# OCP_SOCKET_PRM register map
Vendor: Texas Instruments
Peripheral module from a debugger description file (folder omap5430_ES2_PUBLIC).
Registers are 32-bit, access per field, reset 0x0 unless marked. A register's access mark holds for its fields unless they carry their own. Offsets are as the file gives them; lines under a group give offsets from that group; [hi:lo] are bit positions; {n}, {i} and the like mark numbered series; 'fields as' and 'values as' point back to an identical list; <NAME> marks a mode.

## OCP_SOCKET_PRM
0x00 REVISION_PRM ro reset not defined — This register contains the IP revision code for the PRM part of the PRCM
  [31:0] REV — Revision Number
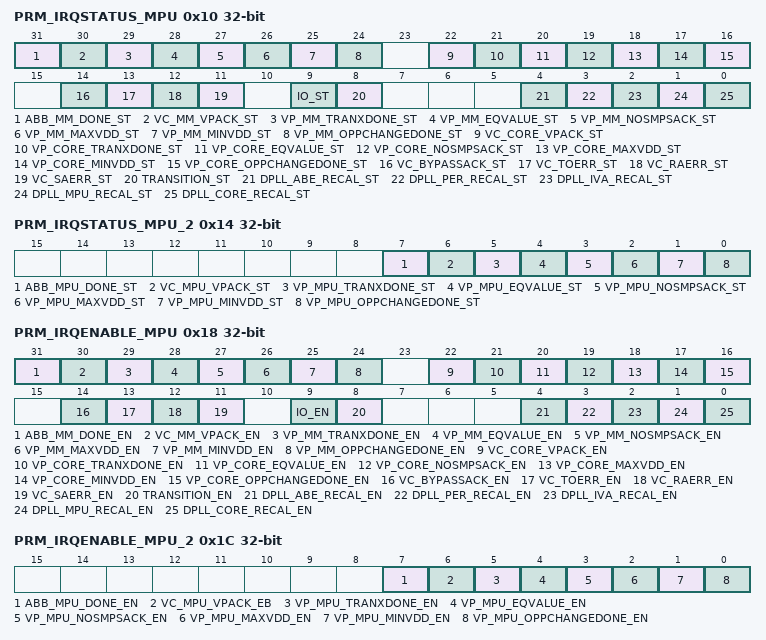
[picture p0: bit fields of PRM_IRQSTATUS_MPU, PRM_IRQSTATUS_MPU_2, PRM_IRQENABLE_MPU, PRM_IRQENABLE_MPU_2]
0x10 PRM_IRQSTATUS_MPU access not given — This register provides status on MPU interrupt events. Any event is logged independently of the corresponding IRQENABLE value. SW is required to clear a set bit by writing a '1' into the bit-position to be cleared.
  [all] fields
    0=IRQ_fal (No interrupt); 1=IRQ_tru (Interrupt is pending)
  [31] ABB_MM_DONE_ST — MM ABB mode change done. This status is set when OPP_CHANGE bit is cleared by hardware in PRM_ABBLDO_MM_CRTL register. It is cleared by SW. (access RW W1toClr)
  [30] VC_MM_VPACK_ST — Voltage Controller MM voltage processor command acknowledge status. (access RW W1toClr)
  [29] VP_MM_TRANXDONE_ST — Voltage Processor MM transaction completion status. This status is set when a transaction is completed in the voltage processor. It is cleared by SW. (access RW W1toClr)
  [28] VP_MM_EQVALUE_ST — Voltage Processor MM voltage value change event. This status is set when an update has been requested but the new voltage value is the same as the current SMPS voltage value. It is cleared by SW. (access RW W1toClr)
  [27] VP_MM_NOSMPSACK_ST — Voltage Processor MM timeout event status. This status is set when the timeout occured before the SMPS acknowledge. It is cleared by SW. (access RW W1toClr)
  [26] VP_MM_MAXVDD_ST — Voltage Processor MM voltage higher limit event status. This status is set when the voltage higher limit is reached. It is cleared by SW. (access RW W1toClr)
  [25] VP_MM_MINVDD_ST — Voltage Processor MM voltage lower limit event status. This status is set when the voltage lower limit is reached. It is cleared by SW. (access RW W1toClr)
  [24] VP_MM_OPPCHANGEDONE_ST — Voltage Processor MM OPP change done status, including ABB mode change done if applicable (OPP_CHANGE bit cleared in PRM_ABBLDO_MM_CRTL). It is cleared by SW. (access RW W1toClr)
  [22] VC_CORE_VPACK_ST — Voltage Controller CORE voltage processor command acknowledge status (access RW W1toClr)
  [21] VP_CORE_TRANXDONE_ST — Voltage Processor CORE transaction completion status. This status is set when a transaction is completed in the voltage processor. It is cleared by SW. (access RW W1toClr)
  [20] VP_CORE_EQVALUE_ST — Voltage Processor CORE voltage value change event. This status is set when an update has been requested but the new voltage value is the same as the current SMPS voltage value. It is cleared by SW. (access RW W1toClr)
  [19] VP_CORE_NOSMPSACK_ST — Voltage Processor CORE timeout event status. This status is set when the timeout occured before the SMPS acknowledge. It is cleared by SW. (access RW W1toClr)
  [18] VP_CORE_MAXVDD_ST — Voltage Processor CORE voltage higher limit event status. This status is set when the voltage higher limit is reached. It is cleared by SW. (access RW W1toClr)
  [17] VP_CORE_MINVDD_ST — Voltage Processor CORE voltage lower limit event status. This status is set when the voltage lower limit is reached. It is cleared by SW. (access RW W1toClr)
  [16] VP_CORE_OPPCHANGEDONE_ST — Voltage Processor CORE OPP change done status. It is cleared by SW. (access RW W1toClr)
  [14] VC_BYPASSACK_ST — Voltage Controller bypass command acknowledge status. (access RW W1toClr)
  [13] VC_TOERR_ST — Voltage Controller timeout error event status. (access RW W1toClr)
  [12] VC_RAERR_ST — Voltage Controller register address acknowledge error event status. (access RW W1toClr)
  [11] VC_SAERR_ST — Voltage Controller slave address acknowledge error event status. (access RW W1toClr)
  [9] IO_ST — IO pad event interrupt status. (access RW W1toClr)
  [8] TRANSITION_ST — Software supervised transition completed event interrupt status (any domain). Asserted upon completion of any clock domain force wakeup transition or upon completion of any power domain sleep transition with at least one enclosed clock domain configured in forced-sleep. (access RW W1toClr)
  [4] DPLL_ABE_RECAL_ST — ABE DPLL recalibration interrupt status. (access RW W1toClr)
  [3] DPLL_PER_RECAL_ST — PER DPLL recalibration interrupt status. (access RW W1toClr)
  [2] DPLL_IVA_RECAL_ST — IVA DPLL recalibration interrupt status. (access RW W1toClr)
  [1] DPLL_MPU_RECAL_ST — MPU DPLL recalibration interrupt status. (access RW W1toClr)
  [0] DPLL_CORE_RECAL_ST — CORE DPLL recalibration interrupt status. (access RW W1toClr)
0x14 PRM_IRQSTATUS_MPU_2 access not given — This register provides status on MPU interrupt events. Any event is logged independently of the corresponding IRQENABLE value. SW is required to clear a set bit by writing a '1' into the bit-position to be cleared.
  [all] fields
    0=IRQ_fal (No interrupt); 1=IRQ_tru (Interrupt is pending)
  [7] ABB_MPU_DONE_ST — MPU ABB mode change done. This status is set when OPP_CHANGE bit is cleared by hardware in PRM_ABBLDO_MPU_CRTL register. It is cleared by SW. (access RW W1toClr)
  [6] VC_MPU_VPACK_ST — Voltage Controller MPU voltage processor command acknowledge status. (access RW W1toClr)
  [5] VP_MPU_TRANXDONE_ST — Voltage Processor MPU transaction completion status. This status is set when a transaction is completed in the voltage processor. It is cleared by SW. (access RW W1toClr)
  [4] VP_MPU_EQVALUE_ST — Voltage Processor MPU voltage value change event. This status is set when an update has been requested but the new voltage value is the same as the current SMPS voltage value. It is cleared by SW. (access RW W1toClr)
  [3] VP_MPU_NOSMPSACK_ST — Voltage Processor MPU timeout event status. This status is set when the timeout occured before the SMPS acknowledge. It is cleared by SW. (access RW W1toClr)
  [2] VP_MPU_MAXVDD_ST — Voltage Processor MPU voltage higher limit event status. This status is set when the voltage higher limit is reached. It is cleared by SW. (access RW W1toClr)
  [1] VP_MPU_MINVDD_ST — Voltage Processor MPU voltage lower limit event status. This status is set when the voltage lower limit is reached. It is cleared by SW. (access RW W1toClr)
  [0] VP_MPU_OPPCHANGEDONE_ST — Voltage Processor MPU OPP change done status, including ABB mode change done if applicable (OPP_CHANGE bit cleared in PRM_ABBLDO_MPU_CRTL). It is cleared by SW. (access RW W1toClr)
0x18 PRM_IRQENABLE_MPU — This register is used to enable or disable MPU interrupt activation upon presence of corresponding bit.
  [31] ABB_MM_DONE_EN rw — MM ABB mode change done enable.
    0=IRQ_fal (Interrupt is masked); 1=IRQ_tru (Interrupt is enabled)
  [30] VC_MM_VPACK_EN rw — Voltage Controller MM voltage processor command acknowledge enable.
    0=irq_msk (Interrupt is masked); 1=irq_en (Interrupt is enabled)
  [29] VP_MM_TRANXDONE_EN rw — Voltage Processor MM transaction completion enable.
    values as VC_MM_VPACK_EN
  [28] VP_MM_EQVALUE_EN rw — Voltage Processor MM voltage value change event enable.
    values as VC_MM_VPACK_EN
  [27] VP_MM_NOSMPSACK_EN rw — Voltage Processor MM timeout event enable.
    values as VC_MM_VPACK_EN
  [26] VP_MM_MAXVDD_EN rw — Voltage Processor MM voltage higher limit event enable.
    values as VC_MM_VPACK_EN
  [25] VP_MM_MINVDD_EN rw — Voltage Processor MM voltage lower limit event enable.
    values as VC_MM_VPACK_EN
  [24] VP_MM_OPPCHANGEDONE_EN rw — Voltage Processor MM OPP change done enable.
    values as VC_MM_VPACK_EN
  [22] VC_CORE_VPACK_EN rw — Voltage Controller CORE voltage processor command acknowledge enable
    values as VC_MM_VPACK_EN
  [21] VP_CORE_TRANXDONE_EN rw — Voltage Processor CORE transaction completion enable.
    values as VC_MM_VPACK_EN
  [20] VP_CORE_EQVALUE_EN rw — Voltage Processor CORE voltage value change event enable.
    values as VC_MM_VPACK_EN
  [19] VP_CORE_NOSMPSACK_EN rw — Voltage Processor CORE timeout event enable.
    values as VC_MM_VPACK_EN
  [18] VP_CORE_MAXVDD_EN rw — Voltage Processor CORE voltage higher limit event enable.
    values as VC_MM_VPACK_EN
  [17] VP_CORE_MINVDD_EN rw — Voltage Processor CORE voltage lower limit event enable.
    values as VC_MM_VPACK_EN
  [16] VP_CORE_OPPCHANGEDONE_EN rw — Voltage Processor CORE OPP change done enable.
    values as VC_MM_VPACK_EN
  [14] VC_BYPASSACK_EN rw — Voltage Controller bypass command acknowledge enable.
    values as VC_MM_VPACK_EN
  [13] VC_TOERR_EN rw — Voltage Controller timeout error event enable.
    values as VC_MM_VPACK_EN
  [12] VC_RAERR_EN rw — Voltage Controller register address acknowledge error event enable.
    values as VC_MM_VPACK_EN
  [11] VC_SAERR_EN rw — Voltage Controller slave address acknowledge error event enable.
    values as VC_MM_VPACK_EN
  [9] IO_EN rw — IO pad event interrupt enable.
    values as VC_MM_VPACK_EN
  [8] TRANSITION_EN rw — Software supervised transition completed event interrupt enable (any domain).
    values as VC_MM_VPACK_EN
  [4] DPLL_ABE_RECAL_EN rw — ABE DPLL recalibration interrupt enable.
    values as VC_MM_VPACK_EN
  [3] DPLL_PER_RECAL_EN rw — PER DPLL recalibration interrupt enable.
    values as VC_MM_VPACK_EN
  [2] DPLL_IVA_RECAL_EN rw — IVA DPLL recalibration interrupt enable.
    values as VC_MM_VPACK_EN
  [1] DPLL_MPU_RECAL_EN rw — MPU DPLL recalibration interrupt enable.
    values as VC_MM_VPACK_EN
  [0] DPLL_CORE_RECAL_EN rw — CORE DPLL recalibration interrupt enable.
    values as VC_MM_VPACK_EN
0x1C PRM_IRQENABLE_MPU_2 — This register is used to enable or disable MPU interrupt activation upon presence of corresponding bit.
  [7] ABB_MPU_DONE_EN rw — MPU ABB mode change done enable.
    values as PRM_IRQENABLE_MPU.ABB_MM_DONE_EN
  [6] VC_MPU_VPACK_EB rw — Voltage Controller MPU voltage processor command acknowledge enable.
    0=Interrupt_is_masked; 1=Interrupt_is_enabled
  [5] VP_MPU_TRANXDONE_EN rw — Voltage Processor MPU transaction completion enable
    values as PRM_IRQENABLE_MPU.VC_MM_VPACK_EN
  [4] VP_MPU_EQVALUE_EN rw — Voltage Processor MPU voltage value change event enable
    values as PRM_IRQENABLE_MPU.VC_MM_VPACK_EN
  [3] VP_MPU_NOSMPSACK_EN rw — Voltage Processor MPU timeout event enable
    values as PRM_IRQENABLE_MPU.VC_MM_VPACK_EN
  [2] VP_MPU_MAXVDD_EN rw — Voltage Processor MPU voltage higher limit event enable
    values as PRM_IRQENABLE_MPU.VC_MM_VPACK_EN
  [1] VP_MPU_MINVDD_EN rw — Voltage Processor MPU voltage lower limit event enable
    values as PRM_IRQENABLE_MPU.VC_MM_VPACK_EN
  [0] VP_MPU_OPPCHANGEDONE_EN rw — Voltage Processor MPU OPP change done enable
    values as PRM_IRQENABLE_MPU.VC_MM_VPACK_EN
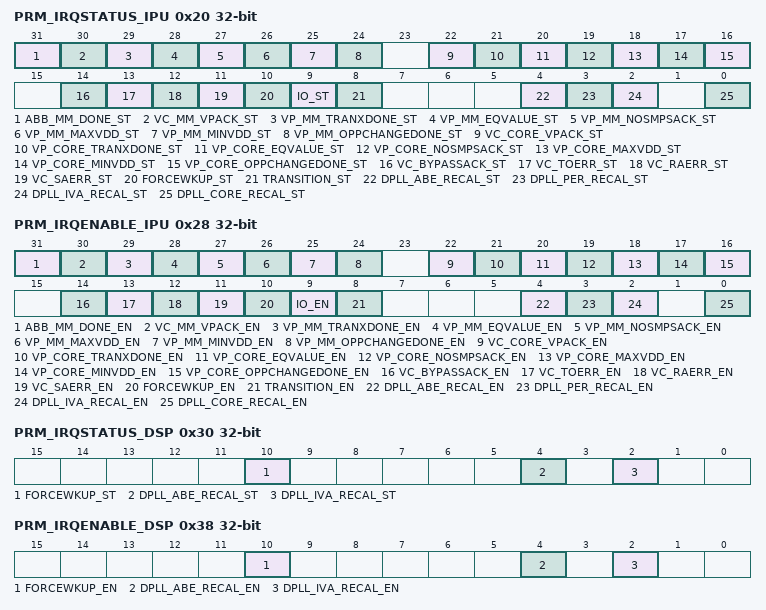
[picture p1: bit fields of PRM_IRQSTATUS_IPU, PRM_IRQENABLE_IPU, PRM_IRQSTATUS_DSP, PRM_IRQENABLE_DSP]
0x20 PRM_IRQSTATUS_IPU access not given — This register provides status on IPU interrupt events. Any event is logged independently of the corresponding IRQENABLE value. SW is required to clear a set bit by writing a '1' into the bit-position to be cleared.
  [all] fields
    0=IRQ_fal (No interrupt); 1=IRQ_tru (Interrupt is pending)
  [31] ABB_MM_DONE_ST — MM ABB mode change done. This status is set when OPP_CHANGE bit is cleared by hardware in PRM_ABBLDO_MM_CRTL register. It is cleared by SW. (access RW W1toClr)
  [30] VC_MM_VPACK_ST — Voltage Controller MM voltage processor command acknowledge status (access RW W1toClr)
  [29] VP_MM_TRANXDONE_ST — Voltage Processor MM transaction completion status. This status is set when a transaction is completed in the voltage processor. It is cleared by SW. (access RW W1toClr)
  [28] VP_MM_EQVALUE_ST — Voltage Processor MM voltage value change event. This status is set when an update has been requested but the new voltage value is the same as the current SMPS voltage value. It is cleared by SW. (access RW W1toClr)
  [27] VP_MM_NOSMPSACK_ST — Voltage Processor MM timeout event status. This status is set when the timeout occured before the SMPS acknowledge. It is cleared by SW. (access RW W1toClr)
  [26] VP_MM_MAXVDD_ST — Voltage Processor MM voltage higher limit event status. This status is set when the voltage higher limit is reached. It is cleared by SW. (access RW W1toClr)
  [25] VP_MM_MINVDD_ST — Voltage Processor MM voltage lower limit event status. This status is set when the voltage lower limit is reached. It is cleared by SW. (access RW W1toClr)
  [24] VP_MM_OPPCHANGEDONE_ST — Voltage Processor MM OPP change done status, including ABB mode change done if applicable (OPP_CHANGE bit cleared in PRM_ABBLDO_MM_CRTL). It is cleared by SW. (access RW W1toClr)
  [22] VC_CORE_VPACK_ST — Voltage Controller CORE voltage processor command acknowledge status (access RW W1toClr)
  [21] VP_CORE_TRANXDONE_ST — Voltage Processor CORE transaction completion status. This status is set when a transaction is completed in the voltage processor. It is cleared by SW. (access RW W1toClr)
  [20] VP_CORE_EQVALUE_ST — Voltage Processor CORE voltage value change event. This status is set when an update has been requested but the new voltage value is the same as the current SMPS voltage value. It is cleared by SW. (access RW W1toClr)
  [19] VP_CORE_NOSMPSACK_ST — Voltage Processor CORE timeout event status. This status is set when the timeout occured before the SMPS acknowledge. It is cleared by SW. (access RW W1toClr)
  [18] VP_CORE_MAXVDD_ST — Voltage Processor CORE voltage higher limit event status. This status is set when the voltage higher limit is reached. It is cleared by SW. (access RW W1toClr)
  [17] VP_CORE_MINVDD_ST — Voltage Processor CORE voltage lower limit event status. This status is set when the voltage lower limit is reached. It is cleared by SW. (access RW W1toClr)
  [16] VP_CORE_OPPCHANGEDONE_ST — Voltage Processor CORE OPP change done status. It is cleared by SW. (access RW W1toClr)
  [14] VC_BYPASSACK_ST — Voltage Controller bypass command acknowledge status (access RW W1toClr)
  [13] VC_TOERR_ST — Voltage Controller timeout error event status (access RW W1toClr)
  [12] VC_RAERR_ST — Voltage Controller register address acknowledge error event status (access RW W1toClr)
  [11] VC_SAERR_ST — Voltage Controller slave address acknowledge error event status (access RW W1toClr)
  [10] FORCEWKUP_ST — IPU domain software supervised wakeup transition completed event interrupt status. (access RW W1toClr)
  [9] IO_ST — IO pad event interrupt status. (access RW W1toClr)
  [8] TRANSITION_ST — Software supervised transition completed event interrupt status (any domain). Asserted upon completion of any clock domain force wakeup transition or upon completion of any power domain sleep transition with at least one enclosed clock domain configured in forced-sleep. (access RW W1toClr)
  [4] DPLL_ABE_RECAL_ST — ABE DPLL recalibration interrupt status. (access RW W1toClr)
  [3] DPLL_PER_RECAL_ST — PER DPLL recalibration interrupt status. (access RW W1toClr)
  [2] DPLL_IVA_RECAL_ST — IVA DPLL recalibration interrupt status. (access RW W1toClr)
  [0] DPLL_CORE_RECAL_ST — CORE DPLL recalibration interrupt status. (access RW W1toClr)
0x28 PRM_IRQENABLE_IPU — This register is used to enable or disable IPU interrupt activation upon presence of corresponding bit.
  [31] ABB_MM_DONE_EN rw — MM ABB mode change done enable
    values as PRM_IRQENABLE_MPU.ABB_MM_DONE_EN
  [30] VC_MM_VPACK_EN rw — Voltage Controller MM voltage processor command acknowledge enable
    values as PRM_IRQENABLE_MPU.VC_MM_VPACK_EN
  [29] VP_MM_TRANXDONE_EN rw — Voltage Processor MM transaction completion enable
    values as PRM_IRQENABLE_MPU.VC_MM_VPACK_EN
  [28] VP_MM_EQVALUE_EN rw — Voltage Processor MM voltage value change event enable
    values as PRM_IRQENABLE_MPU.VC_MM_VPACK_EN
  [27] VP_MM_NOSMPSACK_EN rw — Voltage Processor MM timeout event enable
    values as PRM_IRQENABLE_MPU.VC_MM_VPACK_EN
  [26] VP_MM_MAXVDD_EN rw — Voltage Processor MM voltage higher limit event enable
    values as PRM_IRQENABLE_MPU.VC_MM_VPACK_EN
  [25] VP_MM_MINVDD_EN rw — Voltage Processor MM voltage lower limit event enable
    values as PRM_IRQENABLE_MPU.VC_MM_VPACK_EN
  [24] VP_MM_OPPCHANGEDONE_EN rw — Voltage Processor MM OPP change done enable
    values as PRM_IRQENABLE_MPU.VC_MM_VPACK_EN
  [22] VC_CORE_VPACK_EN rw — Voltage Controller CORE voltage processor command acknowledge enable
    values as PRM_IRQENABLE_MPU.VC_MM_VPACK_EN
  [21] VP_CORE_TRANXDONE_EN rw — Voltage Processor CORE transaction completion enable
    values as PRM_IRQENABLE_MPU.VC_MM_VPACK_EN
  [20] VP_CORE_EQVALUE_EN rw — Voltage Processor CORE voltage value change event enable
    values as PRM_IRQENABLE_MPU.VC_MM_VPACK_EN
  [19] VP_CORE_NOSMPSACK_EN rw — Voltage Processor CORE timeout event enable
    values as PRM_IRQENABLE_MPU.VC_MM_VPACK_EN
  [18] VP_CORE_MAXVDD_EN rw — Voltage Processor CORE voltage higher limit event enable
    values as PRM_IRQENABLE_MPU.VC_MM_VPACK_EN
  [17] VP_CORE_MINVDD_EN rw — Voltage Processor CORE voltage lower limit event enable
    values as PRM_IRQENABLE_MPU.VC_MM_VPACK_EN
  [16] VP_CORE_OPPCHANGEDONE_EN rw — Voltage Processor CORE OPP change done enable
    values as PRM_IRQENABLE_MPU.VC_MM_VPACK_EN
  [14] VC_BYPASSACK_EN rw — Voltage Controller bypass command acknowledge enable
    values as PRM_IRQENABLE_MPU.VC_MM_VPACK_EN
  [13] VC_TOERR_EN rw — Voltage Controller timeout error event enable
    values as PRM_IRQENABLE_MPU.VC_MM_VPACK_EN
  [12] VC_RAERR_EN rw — Voltage Controller register address acknowledge error event enable
    values as PRM_IRQENABLE_MPU.VC_MM_VPACK_EN
  [11] VC_SAERR_EN rw — Voltage Controller slave address acknowledge error event enable
    values as PRM_IRQENABLE_MPU.VC_MM_VPACK_EN
  [10] FORCEWKUP_EN rw — IPU domain software supervised wakeup transition completed event interrupt enable.
    values as PRM_IRQENABLE_MPU.VC_MM_VPACK_EN
  [9] IO_EN rw — IO pad event interrupt enable
    values as PRM_IRQENABLE_MPU.VC_MM_VPACK_EN
  [8] TRANSITION_EN rw — Software supervised transition completed event interrupt enable (any domain)
    values as PRM_IRQENABLE_MPU.VC_MM_VPACK_EN
  [4] DPLL_ABE_RECAL_EN rw — ABEDPLL recalibration interrupt enable
    values as PRM_IRQENABLE_MPU.VC_MM_VPACK_EN
  [3] DPLL_PER_RECAL_EN rw — PER DPLL recalibration interrupt enable
    values as PRM_IRQENABLE_MPU.VC_MM_VPACK_EN
  [2] DPLL_IVA_RECAL_EN rw — IVA DPLL recalibration interrupt enable
    values as PRM_IRQENABLE_MPU.VC_MM_VPACK_EN
  [0] DPLL_CORE_RECAL_EN rw — CORE DPLL recalibration interrupt enable
    values as PRM_IRQENABLE_MPU.VC_MM_VPACK_EN
0x30 PRM_IRQSTATUS_DSP access not given — This register provides status on DSP interrupt events. Any event is logged independently of the corresponding IRQENABLE value. SW is required to clear a set bit by writing a '1' into the bit-position to be cleared.
  [all] fields
    0=IRQ_fal (No interrupt); 1=IRQ_tru (Interrupt is pending)
  [10] FORCEWKUP_ST — DSP domain software supervised wakeup transition completed event interrupt status. (access RW W1toClr)
  [4] DPLL_ABE_RECAL_ST — ABE DPLL recalibration interrupt status. (access RW W1toClr)
  [2] DPLL_IVA_RECAL_ST — IVA DPLL recalibration interrupt status. (access RW W1toClr)
0x38 PRM_IRQENABLE_DSP — This register is used to enable or disable DSP interrupt activation upon presence of corresponding bit.
  [all] fields
    values as PRM_IRQENABLE_MPU.VC_MM_VPACK_EN
  [10] FORCEWKUP_EN rw — DSP domain software supervised wakeup transition completed event interrupt enable.
  [4] DPLL_ABE_RECAL_EN rw — ABEDPLL recalibration interrupt enable
  [2] DPLL_IVA_RECAL_EN rw — IVA DPLL recalibration interrupt enable
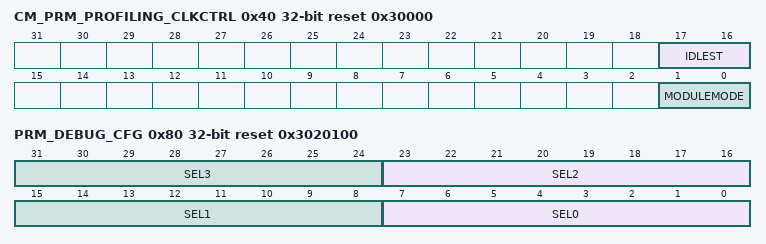
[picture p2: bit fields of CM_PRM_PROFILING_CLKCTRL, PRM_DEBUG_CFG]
0x40 CM_PRM_PROFILING_CLKCTRL reset 0x30000 — This register manages the WKUPAON_PROFILING_GCLK clock. [warm reset insensitive]
  [17:16] IDLEST ro — Module idle status
    0=Func (Module is fully functional); 1=Trans (Module is performing transition: wakeup, or sleep, or sleep abortion); 2=Idle (Module is in Idle); 3=Disable (Module is disabled)
  [1:0] MODULEMODE rw — Control the way mandatory clocks are managed.
    0=DISABLED (Module is disabled by SW. INTRCONN configuration port is not accessible.); 1=AUTO (Module is managed automatically by HW along with EMU domain. INTRCONN configuration port is accessible only when EMU domain is on.)
0x80 PRM_DEBUG_CFG rw reset 0x3020100 — This register is used to configure the PRM's 32-bit debug output. There is one 7-bit source select field for selecting from a shared set of 8-bit internal signal blocks per byte. [warm reset insensitive]
  [8n+7:8n] SEL{n} (n=0..3) — Internal signal block select for debug word byte-{n}
